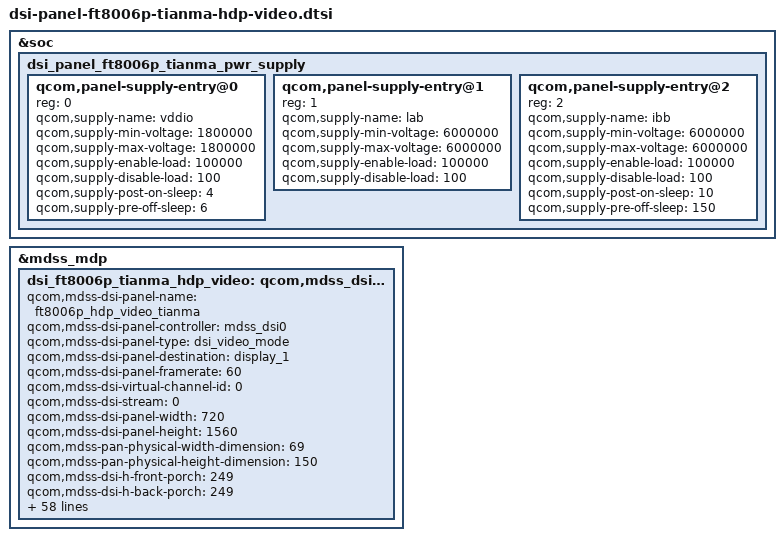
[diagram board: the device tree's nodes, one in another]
/* Copyright (c) 2013, The Linux Foundation. All rights reserved.
 *
 * This program is free software; you can redistribute it and/or modify
 * it under the terms of the GNU General Public License version 2 and
 * only version 2 as published by the Free Software Foundation.
 *
 * This program is distributed in the hope that it will be useful,
 * but WITHOUT ANY WARRANTY; without even the implied warranty of
 * MERCHANTABILITY or FITNESS FOR A PARTICULAR PURPOSE.  See the
 * GNU General Public License for more details.
 */

/*---------------------------------------------------------------------------
 * This file is autogenerated file using gcdb parser. Please do not edit it.
 * Update input XML file to add a new entry or update variable in this file
 * VERSION = "1.0"
 *---------------------------------------------------------------------------*/
&soc {
	dsi_panel_ft8006p_tianma_pwr_supply: dsi_panel_ft8006p_tianma_pwr_supply {
		#address-cells = <1>;
		#size-cells = <0>;

		qcom,panel-supply-entry@0 {
			reg = <0>;
			qcom,supply-name = "vddio";
			qcom,supply-min-voltage = <1800000>;
			qcom,supply-max-voltage = <1800000>;
			qcom,supply-enable-load = <100000>;
			qcom,supply-disable-load = <100>;
			qcom,supply-post-on-sleep = <4>;
			qcom,supply-pre-off-sleep = <6>;
		};
		qcom,panel-supply-entry@1 {
			reg = <1>;
			qcom,supply-name = "lab";
			qcom,supply-min-voltage = <6000000>;
			qcom,supply-max-voltage = <6000000>;
			qcom,supply-enable-load = <100000>;
			qcom,supply-disable-load = <100>;
		};
		qcom,panel-supply-entry@2 {
			reg = <2>;
			qcom,supply-name = "ibb";
			qcom,supply-min-voltage = <6000000>;
			qcom,supply-max-voltage = <6000000>;
			qcom,supply-enable-load = <100000>;
			qcom,supply-disable-load = <100>;
			qcom,supply-post-on-sleep = <10>;
			qcom,supply-pre-off-sleep = <150>;
		};
	};
};
&mdss_mdp {
	dsi_ft8006p_tianma_hdp_video: qcom,mdss_dsi_ft8006p_tianma_hdp_video {
		qcom,mdss-dsi-panel-name = "ft8006p_hdp_video_tianma";
		qcom,mdss-dsi-panel-controller = <&mdss_dsi0>;
		qcom,mdss-dsi-panel-type = "dsi_video_mode";
		qcom,mdss-dsi-panel-destination = "display_1";
		qcom,mdss-dsi-panel-framerate = <60>;
		qcom,mdss-dsi-virtual-channel-id = <0>;
		qcom,mdss-dsi-stream = <0>;
		qcom,mdss-dsi-panel-width = <720>;
		qcom,mdss-dsi-panel-height = <1560>;
		qcom,mdss-pan-physical-width-dimension = <69>;
		qcom,mdss-pan-physical-height-dimension = <150>;
		qcom,mdss-dsi-h-front-porch = <249>;
		qcom,mdss-dsi-h-back-porch = <249>;
		qcom,mdss-dsi-h-pulse-width = <14>;
		qcom,mdss-dsi-h-sync-skew = <0>;
		qcom,mdss-dsi-v-back-porch = <106>;
		qcom,mdss-dsi-v-front-porch = <130>;
		qcom,mdss-dsi-v-pulse-width = <8>;
		qcom,mdss-dsi-h-left-border = <0>;
		qcom,mdss-dsi-h-right-border = <0>;
		qcom,mdss-dsi-v-top-border = <0>;
		qcom,mdss-dsi-v-bottom-border = <0>;
		qcom,mdss-dsi-bpp = <24>;
		qcom,mdss-dsi-color-order = "rgb_swap_rgb";
		qcom,mdss-dsi-underflow-color = <0xff>;
		qcom,mdss-dsi-border-color = <0>;
		qcom,mdss-dsi-on-command = [39 01 00 00 00 00 02 41 5A
					39 01 00 00 00 00 03 41 5A 03
					39 01 00 00 00 00 03 80 A9 00
					39 01 00 00 00 00 03 41 5A 09
					39 01 00 00 00 00 06 80 64 00 64 00 00
					39 01 00 00 00 00 03 41 5A 0A
					39 01 00 00 00 00 11 80 A5 3E A5 AA A5 88 42 68 A6 03 07 01 64 2F 50 23
					39 01 00 00 00 00 11 90 0C 0F 22 00 2A 18 64 00 88 03 00 FF FF 00 3F 2A
					39 01 00 00 00 00 11 A0 00 30 02 32 11 0D 60 01 FF FF 03 40 42 0F 94 11
					39 01 00 00 00 00 11 B0 E8 03 00 00 11 0D 60 00 FF FF 03 FF 34 0C 0F 0E
					39 01 00 00 00 00 0B C0 1F 03 00 08 20 34 00 00 00 00
					39 01 00 00 00 00 03 41 5A 0B
					39 01 00 00 00 00 11 80 FF D2 D2 00 00 0B 21 34 3F 4B 5C 6A 6B 77 77 8A
					39 01 00 00 00 00 11 90 7B 6A 6C 62 5A 4E 3F 35 2C 1B 06 01 00 0B 21 34
					39 01 00 00 00 00 11 A0 3F 4B 5C 6A 6B 77 77 8A 7B 6A 6C 62 5A 4E 3F 35
					39 01 00 00 00 00 06 B0 2C 1B 06 01 00
					39 01 00 00 00 00 03 41 5A 0C
					39 01 00 00 00 00 11 80 00 00 20 42 00 00 80 05 54 00 00 00 20 42 00 00
					39 01 00 00 00 00 03 90 80 05
					39 01 00 00 00 00 03 41 5A 0D
					39 01 00 00 00 00 11 80 7A D0 02 18 06 E7 00 F5 00 0A 0A 0A 0A 00 01 03
					39 01 00 00 00 00 11 90 00 00 00 00 AC A2 2A 00 00 00 AC A2 2A 57 31 00
					39 01 00 00 00 00 11 A0 00 00 00 00 00 AC A2 2A AA C2 2A AC A2 2A AA C2
					39 01 00 00 00 00 07 B0 2A 00 00 00 AA 52
					39 01 00 00 00 00 03 41 5A 0E
					39 01 00 00 00 00 0D 80 F0 B1 71 EF 4B 20 37 0F AA AA 00 00
					39 01 00 00 00 00 03 41 5A 0F
					39 01 00 00 00 00 0C 80 FF 00 55 55 23 88 88 1C 00 5A 5A
					39 01 00 00 00 00 03 41 5A 10
					39 01 00 00 00 00 11 80 B5 45 09 18 01 3C 94 32 10 C4 C4 04 00 60 C0 00
					39 01 00 00 00 00 11 90 04 00 00 86 10 31 98 34 34 34 26 26 3E 1A 62 20
					39 01 00 00 00 00 05 A0 0C 40 00 8A
					39 01 00 00 00 00 03 41 5A 11
					39 01 00 00 00 00 11 80 00 00 03 E7 1F 17 00 48 70 42 90 1A 30 88 41 8A
					39 01 00 00 00 00 10 90 39 28 A9 C5 9A 7B F0 07 7E E0 07 7E 20 10 00
					39 01 00 00 00 00 03 41 5A 12
					39 01 00 00 00 00 11 80 00 00 00 00 00 01 00 00 00 00 00 01 00 03 41 37
					39 01 00 00 00 00 11 90 2D 23 19 0F 05 FB 05 FB 00 00 00 00 00 00 00 00
					39 01 00 00 00 00 11 A0 00 00 00 00 00 00 00 00 00 00 00 00 14 00 00 02
					39 01 00 00 00 00 11 B0 00 00 00 00 00 00 00 00 00 2D 23 0C 07 25 2D 23
					39 01 00 00 00 00 05 C0 05 FB 00 01
					39 01 00 00 00 00 03 41 5A 13
					39 01 00 00 00 00 11 80 FD 0F 00 0C 00 80 80 82 00 07 22 06 E7 B9 86 1A
					39 01 00 00 00 00 11 90 32 00 A2 2D 65 00 00 00 00 D0 C9 B7 FE 26 6F 32
					39 01 00 00 00 00 04 A0 22 90 04
					39 01 00 00 00 00 03 41 5A 14
					39 01 00 00 00 00 11 80 01 02 40 5E D1 DF EF F7 FB FD 02 00 00 0C 8B 8B
					39 01 00 00 00 00 11 90 11 7C 40 3C 8C E0 03 62 65 04 1F 10 2B 23 F8 00
					39 01 00 00 00 00 11 A0 00 F8 FD 00 00 C0 EF 07 00 18 06 6B C5 EF 8F 00
					39 01 00 00 00 00 11 B0 B0 13 BF 3F 02 00 00 00 00 B8 61 1B 56 00 80 42
					39 01 00 00 00 00 11 C0 A1 F0 16 E8 64 02 00 00 DE 01 9D 4C 00 00 C0 1B
					39 01 00 00 00 00 11 D0 A0 93 09 00 00 78 01 74 32 01 00 00 AF 80 4E 26
					39 01 00 00 00 00 11 E0 00 00 E0 25 D0 C9 04 00 00 BC 06 3A 99 00 00 80
					39 01 00 00 00 00 11 F0 17 41 27 13 00 00 30 06 7E 3F 14 00 00 00 00 00
					39 01 00 00 00 00 03 41 5A 15
					39 01 00 00 00 00 11 80 00 00 00 00 00 00 00 00 00 00 00 00 0C 80 FF EF
					39 01 00 00 00 00 11 90 27 03 1B C6 88 51 AB 0D A1 D5 FE 62 D4 6A 43 68
					39 01 00 00 00 00 11 A0 B5 00 00 00 00 00 00 00 00 00 00 00 00 00 00 00
					39 01 00 00 00 00 11 B0 00 00 00 00 00 00 00 00 26 00 E0 01 28 66 1A 56
					39 01 00 00 00 00 11 C0 97 69 46 93 A3 18 42 DB B6 6D DB B6 6D DB B6 6D
					39 01 00 00 00 00 11 D0 DB B6 6D DB B6 6D DB B6 6D DB B6 6D DB B6 6D 1A
					39 01 00 00 00 00 11 E0 52 96 69 42 12 83 10 40 DB B6 6D DB B6 6D DB B6
					39 01 00 00 00 00 11 F0 6D DB B6 6D DB B6 6D DB B6 6D DB B6 6D DB B6 A4
					39 01 00 00 00 00 03 41 5A 16
					39 01 00 00 00 00 11 80 82 82 82 02 00 00 00 00 00 00 00 00 00 00 00 00
					39 01 00 00 00 00 0B 90 00 00 00 00 80 42 29 01 00 00
					39 01 00 00 00 00 03 41 5A 18
					39 01 00 00 00 00 11 80 EF BD F7 DE 7B EF BD 07 08 08 0A 0C 0C 0C 0C 0C
					39 01 00 00 00 00 11 90 0C 0C 0C 5C 09 A8 AA AA AA AA AA AA AA AA AA 5A
					39 01 00 00 00 00 11 A0 59 59 59 59 59 59 59 59 59 59 59 09 04 FF 00 80
					39 01 00 00 00 00 10 B0 80 00 04 20 00 01 08 40 00 02 10 80 00 04 00
					39 01 00 00 00 00 03 41 5A 19
					39 01 00 00 00 00 11 80 81 80 80 80 80 80 80 80 80 80 80 80 00 50 F6 CF
					39 01 00 00 00 00 11 90 FC 6F F6 AF CF AF 0F FF AF B5 71 0E 6C 4A 69 08
					39 01 00 00 00 00 05 A0 00 00 66 00
					39 01 00 00 00 00 03 41 5A 1A
					39 01 00 00 00 00 11 80 FF 00 04 08 0C 50 10 14 18 1C A5 20 28 30 39 3E
					39 01 00 00 00 00 11 90 41 49 51 59 94 61 69 71 79 FA 81 8A 92 9A 03 A2
					39 01 00 00 00 00 11 A0 AA B2 BA 00 C2 CA D1 D9 F0 E1 E9 F0 F8 06 FC FE
					39 01 00 00 00 00 11 B0 FF 00 00 04 08 0C 00 10 14 18 1C 00 20 28 30 37
					39 01 00 00 00 00 11 C0 C0 3F 47 4F 57 FF 5F 67 6F 77 FF 7F 87 8F 97 FF
					39 01 00 00 00 00 11 D0 9F A7 AF B7 FF BF C7 CF D7 FF E0 E8 F0 F8 00 FC
					39 01 00 00 00 00 11 E0 FE FF 00 00 03 07 0B 6C 0F 12 16 1A 6C 1E 26 2E
					39 01 00 00 00 00 11 F0 35 C0 3D 45 4D 55 1A 5C 64 6C 73 C7 7B 83 8B 92
					39 01 00 00 00 00 03 41 5A 1B
					39 01 00 00 00 00 11 80 86 9A A2 A9 B1 B1 B9 C1 C8 D0 F1 D8 E0 E9 F1 AF
					39 01 00 00 00 00 06 90 F5 F7 F8 15 00
					39 01 00 00 00 00 03 41 5A 1C
					39 01 00 00 00 00 11 80 33 22 00 03 5A 02 5A 54 E5 FF C7 00 18 28 18 08
					39 01 00 00 00 00 11 90 10 0C 07 09 06 06 0A 10 0C 09 0B 06 26 F2 78 40
					39 01 00 00 00 00 11 A0 20 08 08 06 13 C0 34 1E 0A 08 66 D1 A0 1C 20 20
					39 01 00 00 00 00 11 B0 18 04 20 00 C0 04 28 01 4C 00 23 18 10 0A 06 C9
					39 01 00 00 00 00 11 C0 04 70 41 58 54 B5 4A 55 15 00 78 F8 99 99 99 99
					39 01 00 00 00 00 11 D0 99 19 11 11 11 11 11 11 10 C0 E3 81 00 20 80 27
					39 01 00 00 00 00 11 E0 E2 89 00 00 00 00 40 00 00 31 04 41 B6 6D DB B6
					39 01 00 00 00 00 11 F0 6D DB B6 6D DB B6 6D DB B6 6D DB B6 6D C0 03 40
					39 01 00 00 00 00 03 41 5A 1D
					39 01 00 00 00 00 11 80 00 01 54 0B 23 18 00 00 80 00 00 00 00 00 00 00
					39 01 00 00 00 00 03 41 5A 22
					39 01 00 00 00 00 10 80 00 5E 00 00 00 00 00 00 5E 00 00 00 00 00 00
					39 01 00 00 00 00 03 41 5A 24
					39 01 00 00 00 00 11 80 2D D3 00 55 55 55 55 55 55 55 55 1F 00 AA 3E 00
					39 01 00 00 00 00 05 90 00 00 00 00
					39 01 00 00 00 00 03 41 5A 25
					39 01 00 00 00 00 11 80 01 05 00 05 00 00 00 00 00 00 00 00 00 00 00 00
					39 01 00 00 00 00 0C 90 00 00 00 24 00 00 00 00 FF 07 35
					39 01 00 00 00 00 03 41 5A 26
					39 01 00 00 00 00 11 80 00 83 00 FB BF 60 00 01 00 00 00 00 00 00 BA 93
					39 01 00 00 00 00 04 90 5A A5 5A
					39 01 00 00 00 00 02 90 A5
					39 01 00 00 00 00 03 41 00 2F
					39 01 00 00 00 00 02 4C 03
					39 01 00 00 00 00 03 51 00 00
					39 01 00 00 00 00 02 53 24
					39 01 00 00 00 00 02 55 00  // cabc function, now it close, if want open set 55 01
					05 01 00 00 78 00 01 11
					05 01 00 00 0A 00 01 29];
		qcom,mdss-dsi-off-command = [05 01 00 00 14 00 02 28 00
					05 01 00 00 96 00 02 10 00
					39 01 00 00 00 00 03 41 5a 0e
					39 01 00 00 00 00 02 80 70
					39 01 00 00 00 00 03 41 01 2f];
		qcom,mdss-dsi-on-command-state = "dsi_lp_mode";
		qcom,mdss-dsi-off-command-state = "dsi_lp_mode";
		qcom,mdss-dsi-h-sync-pulse = <1>;
		qcom,mdss-dsi-traffic-mode = "burst_mode";
		qcom,mdss-dsi-lane-map = "lane_map_0123";
		qcom,mdss-dsi-bllp-eof-power-mode;
		qcom,mdss-dsi-bllp-power-mode;
		qcom,mdss-dsi-lane-0-state;
		qcom,mdss-dsi-lane-1-state;
		qcom,mdss-dsi-lane-2-state;
		qcom,mdss-dsi-lane-3-state;
		//qcom,suspend-ulps-enabled;

		qcom,mdss-dsi-panel-timings-phy-v2 = [22 1E 07 08 04 03 04 a0
						22 1E 07 08 04 03 04 a0
						22 1E 07 08 04 03 04 a0
						22 1E 07 08 04 03 04 a0
						22 18 07 08 04 03 04 a0];
		qcom,mdss-dsi-t-clk-post = <0x0D>;
		qcom,mdss-dsi-t-clk-pre = <0x2C>;
		qcom,mdss-dsi-bl-pmic-control-type = "bl_ctrl_dcs";
		qcom,mdss-dsi-bl-min-level = <1>;
		qcom,mdss-dsi-bl-max-level = <255>;
		ss,blmap-size = <256>;
		ss,blmap = < 0 1 1 1 1 1 1 1 1 1
					1 1 2 3 4 5 6 7 8 9
					10 11 12 13 14 15 16 17 18 19
					20 21 22 23 24 25 26 27 28 29
					30 31 32 33 34 35 36 37 38 39
					40 41 42 43 44 45 46 47 48 49
					50 51 52 53 54 55 56 57 58 59
					60 61 62 63 64 65 66 67 68 69
					70 71 72 73 74 75 76 77 78 79
					80 81 82 83 84 85 86 87 88 89
					90 91 92 93 94 95 96 97 98 99
					100 101 102 103 104 105 106 107 108 109
					110 111 112 113 114 115 116 117 118 119
					120 121 122 123 124 125 126 127 128 129
					130 131 132 133 134 135 136 137 138 139
					140 141 142 143 144 145 146 147 148 149
					150 151 152 153 154 155 156 157 158 159
					160 161 162 163 164 165 166 167 168 169
					170 171 172 173 174 175 176 177 178 179
					180 181 182 183 184 185 186 187 188 189
					190 191 192 193 194 195 196 197 198 199
					200 201 202 203 204 205 206 207 208 209
					210 211 212 213 214 215 216 217 218 219
					220 221 222 223 224 225 226 227 228 229
					230 231 232 233 234 236 238 240 242 244
					246 248 250 252 254 255>;

		qcom,mdss-dsi-dma-trigger = "trigger_sw";
		qcom,mdss-dsi-mdp-trigger = "none";
		qcom,mdss-dsi-lp11-init;
		qcom,mdss-dsi-init-delay-us = <5000>;
		qcom,mdss-dsi-reset-sequence = <1 10>, <0 7>, <1 20>;
		qcom,panel-name-id = <2>;
		//Chk 40244, wangcong.wt, modify ,2020/11/30, open ESD recovery
		qcom,esd-check-enabled;
		qcom,mdss-dsi-panel-status-command = [06 01 00 01 05 00 02 0A 08];
		qcom,mdss-dsi-panel-status-command-state = "dsi_lp_mode";
		qcom,mdss-dsi-panel-status-check-mode = "reg_read";
		qcom,mdss-dsi-panel-status-valid-params = <1>;
		qcom,mdss-dsi-panel-status-value = <0x9C>;
		qcom,mdss-dsi-panel-status-read-length = <1>;
		qcom,mdss-dsi-tx-eot-append;
		qcom,panel-supply-entries = <&dsi_panel_ft8006p_tianma_pwr_supply>;
	};
};
